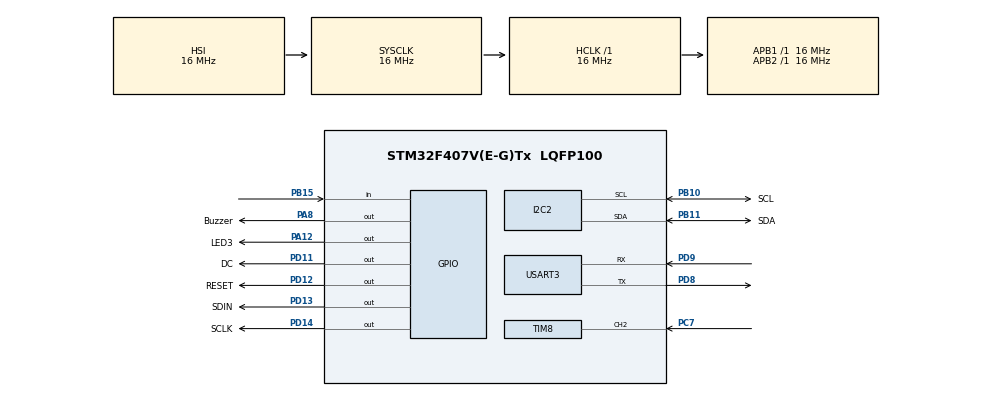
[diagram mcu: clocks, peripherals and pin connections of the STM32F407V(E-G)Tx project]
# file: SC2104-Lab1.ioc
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Mcu.Family=STM32F4
Mcu.Name=STM32F407V(E-G)Tx
Mcu.Package=LQFP100
NVIC.PriorityGroup=NVIC_PRIORITYGROUP_4
NVIC.TIM8_CC_IRQn=true\:0\:0\:false\:false\:true\:true\:true\:true
PA12.GPIO_Label=LED3
PA12.Signal=GPIO_Output
PA13.Signal=SYS_JTMS-SWDIO
PA14.Signal=SYS_JTCK-SWCLK
PA8.GPIO_Label=Buzzer
PA8.Signal=GPIO_Output
PB10.GPIO_Label=SCL
PB10.Mode=I2C
PB10.Signal=I2C2_SCL
PB11.GPIO_Label=SDA
PB11.Mode=I2C
PB11.Signal=I2C2_SDA
PB15.Signal=GPIO_Input
PC7.Signal=S_TIM8_CH2
PD11.GPIO_Label=DC
PD11.Signal=GPIO_Output
PD12.GPIO_Label=RESET
PD12.Signal=GPIO_Output
PD13.GPIO_Label=SDIN
PD13.Signal=GPIO_Output
PD14.GPIO_Label=SCLK
PD14.Signal=GPIO_Output
PD8.Mode=Asynchronous
PD8.Signal=USART3_TX
PD9.Mode=Asynchronous
PD9.Signal=USART3_RX
ProjectManager.HeapSize=0x200
ProjectManager.StackSize=0x400
ProjectManager.TargetToolchain=STM32CubeIDE
RCC.AHBFreq_Value=16000000
RCC.APB1Freq_Value=16000000
RCC.APB2Freq_Value=16000000
RCC.CortexFreq_Value=16000000
RCC.HSE_VALUE=25000000
RCC.HSI_VALUE=16000000
RCC.LSE_VALUE=32768
RCC.SYSCLKFreq_VALUE=16000000
RCC.VCOOutputFreq_Value=192000000
SH.S_TIM8_CH2.0=TIM8_CH2,Input_Capture2_from_TI2
TIM8.Channel-Input_Capture2_from_TI2=TIM_CHANNEL_2
USART3.VirtualMode=VM_ASYNC
VP_TIM6_VS_ClockSourceINT.Mode=Enable_Timer
VP_TIM8_VS_ClockSourceINT.Mode=Internal
board=custom

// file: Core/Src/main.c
/* USER CODE BEGIN Header */
/**
  ******************************************************************************
  * @file           : main.c
  * @brief          : Main program body
  ******************************************************************************
  * @attention
  *
  * Copyright (c) 2023 STMicroelectronics.
  * All rights reserved.
  *
  * This software is licensed under terms that can be found in the LICENSE file
  * in the root directory of this software component.
  * If no LICENSE file comes with this software, it is provided AS-IS.
  *
  ******************************************************************************
  */
/* USER CODE END Header */
#include "main.h"
#include "MPU6050.h"
/* USER CODE BEGIN Includes */
#include "oled.h"
/* USER CODE END Includes */

 I2C_HandleTypeDef hi2c2;

TIM_HandleTypeDef htim6;
TIM_HandleTypeDef htim8;

UART_HandleTypeDef huart3;
IMU_Data imu;

void SystemClock_Config(void);
static void MX_GPIO_Init(void);
static void MX_USART3_UART_Init(void);
static void MX_TIM6_Init(void);
static void MX_TIM8_Init(void);
static void MX_I2C2_Init(void);
/* USER CODE BEGIN PFP */
uint8_t IMU_ADDR = 0xD0;

/* USER CODE END PFP */

int main(void)
{
  /* USER CODE BEGIN 1 */
  uint8_t *OLED_buf;
  /* USER CODE END 1 */

  /* MCU Configuration--------------------------------------------------------*/

  /* Reset of all peripherals, Initializes the Flash interface and the Systick. */
  HAL_Init();

  /* Configure the system clock */
  SystemClock_Config();

  /* Initialize all configured peripherals */
  MX_GPIO_Init();
  MX_USART3_UART_Init();
  MX_TIM6_Init();
  MX_TIM8_Init();
  MX_I2C2_Init();
  /* USER CODE BEGIN 2 */
  /*
  OLED_Init();
  OLED_ShowString(10, 5, "SC2104/CE3002"); //show message on OLED display at line 10
  OLED_Refresh_Gram(); //show message

  HAL_Delay(2000); // display for 2 seconds
  OLED_Clear();    // clear the display

  OLED_buf= "Lab 1"; //another way to show message through buffer
  OLED_ShowString(40,30, OLED_buf); //another message at line 40
  OLED_Refresh_Gram(); //show message

  HAL_UART_Transmit(&huart3, sbuf, sizeof(sbuf), HAL_MAX_DELAY); //message can be sent through the serial plot
  */
  float gRoll = 0.0, gPitch = 0.0, gYaw = 0.0;
  float gRollVar = 2*2, gPitchVar = 2*2;
  float Var_G = 4*4, Var_A = 3*3;
  bool isFirst = true;
  uint8_t status = IMU_Initialise(&imu, &hi2c2, &huart3);
  char sbuf[86] = { 0 };
  //Gyro_calibrate();
  /* USER CODE END 2 */

  /* Infinite loop */
  while (1)
  {
	  IMU_AccelRead(&imu);
	  IMU_GyroRead(&imu);

	  uint32_t millisOld, millisNow; //time value
	  float dt; //time elapse

	  millisNow = HAL_GetTick(); //get the current iime
	  	  dt = (millisNow - millisOld) * 0.001; // time elapse in s
	  	  millisOld = millisNow; // store the current time for next round

	  	  if(!isFirst){ //DUMP FIRST READING SINCE DT NOT KNOWN, INTEGRATE OVER TIMESTEPS
	  		  gPitch = (gPitch + imu.gyro[1]*dt);
	  		  gRoll = (gRoll + imu.gyro[0]*dt);
	  		  gYaw = (gYaw + imu.gyro[2]*dt);
	  	  }else isFirst = false;

	  	  //find pitch and roll in degrees
	  	  float aPitch = atan2(imu.acc[0], imu.acc[2]) * (180/3.1415); //arctan(x/z)
	  	  float aRoll = atan2(imu.acc[1], imu.acc[2]) * (180/3.1415); //arctan(y/z)
	      /*************************/

	      //Complimentary Filter
	      float compPitch = 0.1 * aPitch + 0.9 * (compPitch + imu.gyro[1] * dt);
	      float compRoll = 0.1 * aRoll + 0.9 * (compRoll + imu.gyro[0] * dt);
	      /*************************/

	      //Kalman Filter
	      gPitchVar = gPitchVar + (dt*dt*Var_G);
	      gRollVar = gRollVar + (dt*dt*Var_G); //calculate the uncertainty of the process estimate

	      float KGPitch = gPitchVar/(gPitchVar + Var_A);
	      float KGRoll = gRollVar/(gRollVar + Var_A); //calculate the kalman gain

	      float KFPitch = gPitch + KGPitch*(aPitch - gPitch);
	      float KFRoll = gRoll + KGRoll*(aRoll - gRoll); //calculate the corrected estimates

	      gPitch = KFPitch;
	      gRoll = KFRoll; //post update values
	      gPitchVar = (1-KGPitch)*gPitchVar;
	      gRollVar = (1-KGRoll)*gRollVar;
	      /*************************/

	  	  memset(sbuf, 0, 86);
	  	  sprintf(sbuf, "%5.2f,%5.2f,%5.2f,%5.2f\n", compPitch, KFPitch, gPitch, aPitch);
	  	  HAL_UART_Transmit(&huart3, sbuf, strlen(sbuf), HAL_MAX_DELAY);
	  	  HAL_Delay(100);

  }
}

void SystemClock_Config(void)
{
  RCC_OscInitTypeDef RCC_OscInitStruct = {0};
  RCC_ClkInitTypeDef RCC_ClkInitStruct = {0};

  /** Configure the main internal regulator output voltage
  */
  __HAL_RCC_PWR_CLK_ENABLE();
  __HAL_PWR_VOLTAGESCALING_CONFIG(PWR_REGULATOR_VOLTAGE_SCALE1);

  /** Initializes the RCC Oscillators according to the specified parameters
  * in the RCC_OscInitTypeDef structure.
  */
  RCC_OscInitStruct.OscillatorType = RCC_OSCILLATORTYPE_HSI;
  RCC_OscInitStruct.HSIState = RCC_HSI_ON;
  RCC_OscInitStruct.HSICalibrationValue = RCC_HSICALIBRATION_DEFAULT;
  RCC_OscInitStruct.PLL.PLLState = RCC_PLL_NONE;
  if (HAL_RCC_OscConfig(&RCC_OscInitStruct) != HAL_OK)
  {
    Error_Handler();
  }

  /** Initializes the CPU, AHB and APB buses clocks
  */
  RCC_ClkInitStruct.ClockType = RCC_CLOCKTYPE_HCLK|RCC_CLOCKTYPE_SYSCLK
                              |RCC_CLOCKTYPE_PCLK1|RCC_CLOCKTYPE_PCLK2;
  RCC_ClkInitStruct.SYSCLKSource = RCC_SYSCLKSOURCE_HSI;
  RCC_ClkInitStruct.AHBCLKDivider = RCC_SYSCLK_DIV1;
  RCC_ClkInitStruct.APB1CLKDivider = RCC_HCLK_DIV1;
  RCC_ClkInitStruct.APB2CLKDivider = RCC_HCLK_DIV1;

  if (HAL_RCC_ClockConfig(&RCC_ClkInitStruct, FLASH_LATENCY_0) != HAL_OK)
  {
    Error_Handler();
  }
}

static void MX_I2C2_Init(void)
{

  hi2c2.Instance = I2C2;
  hi2c2.Init.ClockSpeed = 100000;
  hi2c2.Init.DutyCycle = I2C_DUTYCYCLE_2;
  hi2c2.Init.OwnAddress1 = 0;
  hi2c2.Init.AddressingMode = I2C_ADDRESSINGMODE_7BIT;
  hi2c2.Init.DualAddressMode = I2C_DUALADDRESS_DISABLE;
  hi2c2.Init.OwnAddress2 = 0;
  hi2c2.Init.GeneralCallMode = I2C_GENERALCALL_DISABLE;
  hi2c2.Init.NoStretchMode = I2C_NOSTRETCH_DISABLE;
  if (HAL_I2C_Init(&hi2c2) != HAL_OK)
  {
    Error_Handler();
  }

}

static void MX_TIM6_Init(void)
{

  TIM_MasterConfigTypeDef sMasterConfig = {0};

  htim6.Instance = TIM6;
  htim6.Init.Prescaler = 0;
  htim6.Init.CounterMode = TIM_COUNTERMODE_UP;
  htim6.Init.Period = 65535;
  htim6.Init.AutoReloadPreload = TIM_AUTORELOAD_PRELOAD_DISABLE;
  if (HAL_TIM_Base_Init(&htim6) != HAL_OK)
  {
    Error_Handler();
  }
  sMasterConfig.MasterOutputTrigger = TIM_TRGO_RESET;
  sMasterConfig.MasterSlaveMode = TIM_MASTERSLAVEMODE_DISABLE;
  if (HAL_TIMEx_MasterConfigSynchronization(&htim6, &sMasterConfig) != HAL_OK)
  {
    Error_Handler();
  }

}

static void MX_TIM8_Init(void)
{

  TIM_ClockConfigTypeDef sClockSourceConfig = {0};
  TIM_MasterConfigTypeDef sMasterConfig = {0};
  TIM_IC_InitTypeDef sConfigIC = {0};

  htim8.Instance = TIM8;
  htim8.Init.Prescaler = 0;
  htim8.Init.CounterMode = TIM_COUNTERMODE_UP;
  htim8.Init.Period = 65535;
  htim8.Init.ClockDivision = TIM_CLOCKDIVISION_DIV1;
  htim8.Init.RepetitionCounter = 0;
  htim8.Init.AutoReloadPreload = TIM_AUTORELOAD_PRELOAD_DISABLE;
  if (HAL_TIM_Base_Init(&htim8) != HAL_OK)
  {
    Error_Handler();
  }
  sClockSourceConfig.ClockSource = TIM_CLOCKSOURCE_INTERNAL;
  if (HAL_TIM_ConfigClockSource(&htim8, &sClockSourceConfig) != HAL_OK)
  {
    Error_Handler();
  }
  if (HAL_TIM_IC_Init(&htim8) != HAL_OK)
  {
    Error_Handler();
  }
  sMasterConfig.MasterOutputTrigger = TIM_TRGO_RESET;
  sMasterConfig.MasterSlaveMode = TIM_MASTERSLAVEMODE_DISABLE;
  if (HAL_TIMEx_MasterConfigSynchronization(&htim8, &sMasterConfig) != HAL_OK)
  {
    Error_Handler();
  }
  sConfigIC.ICPolarity = TIM_INPUTCHANNELPOLARITY_RISING;
  sConfigIC.ICSelection = TIM_ICSELECTION_DIRECTTI;
  sConfigIC.ICPrescaler = TIM_ICPSC_DIV1;
  sConfigIC.ICFilter = 0;
  if (HAL_TIM_IC_ConfigChannel(&htim8, &sConfigIC, TIM_CHANNEL_2) != HAL_OK)
  {
    Error_Handler();
  }

}

static void MX_USART3_UART_Init(void)
{

  huart3.Instance = USART3;
  huart3.Init.BaudRate = 115200;
  huart3.Init.WordLength = UART_WORDLENGTH_8B;
  huart3.Init.StopBits = UART_STOPBITS_1;
  huart3.Init.Parity = UART_PARITY_NONE;
  huart3.Init.Mode = UART_MODE_TX_RX;
  huart3.Init.HwFlowCtl = UART_HWCONTROL_NONE;
  huart3.Init.OverSampling = UART_OVERSAMPLING_16;
  if (HAL_UART_Init(&huart3) != HAL_OK)
  {
    Error_Handler();
  }

}

static void MX_GPIO_Init(void)
{
  GPIO_InitTypeDef GPIO_InitStruct = {0};

  /* GPIO Ports Clock Enable */
  __HAL_RCC_GPIOB_CLK_ENABLE();
  __HAL_RCC_GPIOD_CLK_ENABLE();
  __HAL_RCC_GPIOC_CLK_ENABLE();
  __HAL_RCC_GPIOA_CLK_ENABLE();

  /*Configure GPIO pin Output Level */
  HAL_GPIO_WritePin(GPIOD, DC_Pin|RESET_Pin|SDIN_Pin|SCLK_Pin, GPIO_PIN_RESET);

  /*Configure GPIO pin Output Level */
  HAL_GPIO_WritePin(GPIOA, Buzzer_Pin|LED3_Pin, GPIO_PIN_RESET);

  /*Configure GPIO pin : PB15 */
  GPIO_InitStruct.Pin = GPIO_PIN_15;
  GPIO_InitStruct.Mode = GPIO_MODE_INPUT;
  GPIO_InitStruct.Pull = GPIO_NOPULL;
  HAL_GPIO_Init(GPIOB, &GPIO_InitStruct);

  /*Configure GPIO pins : DC_Pin RESET_Pin SDIN_Pin SCLK_Pin */
  GPIO_InitStruct.Pin = DC_Pin|RESET_Pin|SDIN_Pin|SCLK_Pin;
  GPIO_InitStruct.Mode = GPIO_MODE_OUTPUT_PP;
  GPIO_InitStruct.Pull = GPIO_NOPULL;
  GPIO_InitStruct.Speed = GPIO_SPEED_FREQ_LOW;
  HAL_GPIO_Init(GPIOD, &GPIO_InitStruct);

  /*Configure GPIO pins : Buzzer_Pin LED3_Pin */
  GPIO_InitStruct.Pin = Buzzer_Pin|LED3_Pin;
  GPIO_InitStruct.Mode = GPIO_MODE_OUTPUT_PP;
  GPIO_InitStruct.Pull = GPIO_NOPULL;
  GPIO_InitStruct.Speed = GPIO_SPEED_FREQ_LOW;
  HAL_GPIO_Init(GPIOA, &GPIO_InitStruct);

}

/* USER CODE BEGIN 4 */
int echo = 0; //for storing the echo pulse duration
int tc1, tc2;

int caldistance (){

}

/*void delay_us(uint16_t us){
  //Start the TIM6 timer
  HAL_TIM_Base_Start(&htim6);

  // Wait until the specified time elapses
  HAL_TIM_SET_COUNTER(&htim6, 0);
  while (HAL_TIM_GET_COUNTER(&htim6) < us);

  // Stop the TIM6 timer
  HAL_TIM_Base_Stop(&htim6);
}*/

/*void HAL_TIM_IC_CaptureCallback(TIM_HandleTypeDef *htim){
	if(htim==&htim8){
    if (htim->Channel == HAL_TIM_ACTIVE_CHANNEL_1) {
            // Capture occurred on channel 1
            uint32_t capturedValue = TIM8->CCR1;
            // Determine the edge (rising or falling)
            if (capturedValue >= previousCaptureValue) {
                // Rising edge
                tc1 = HAL_TIM_ReadCapturedValue(htim, TIM_Channel_2);
            }
            else {
                // Falling edge
                tc2 = HAL_TIM_ReadCapturedValue(htim, TIM_Channel_2);
            }

            previousCaptureValue = capturedValue;
	  }
  }

}*/
/* USER CODE END 4 */

void Error_Handler(void)
{
  __disable_irq();
  while (1)
  {
  }
}
